# csi_tx_if_v2_0_TX_SHIM_VBUSP_MMR_CSI2TXIF_V2 register map
Vendor: Texas Instruments
Peripheral module from a debugger description file (folder J721S2).
Registers are 32-bit, read-write, reset 0x0 unless marked. A register's access mark holds for its fields unless they carry their own. Offsets are as the file gives them; lines under a group give offsets from that group; [hi:lo] are bit positions; {n}, {i} and the like mark numbered series; 'fields as' and 'values as' point back to an identical list; <NAME> marks a mode.

## csi_tx_if_v2_0_TX_SHIM_VBUSP_MMR_CSI2TXIF_V2
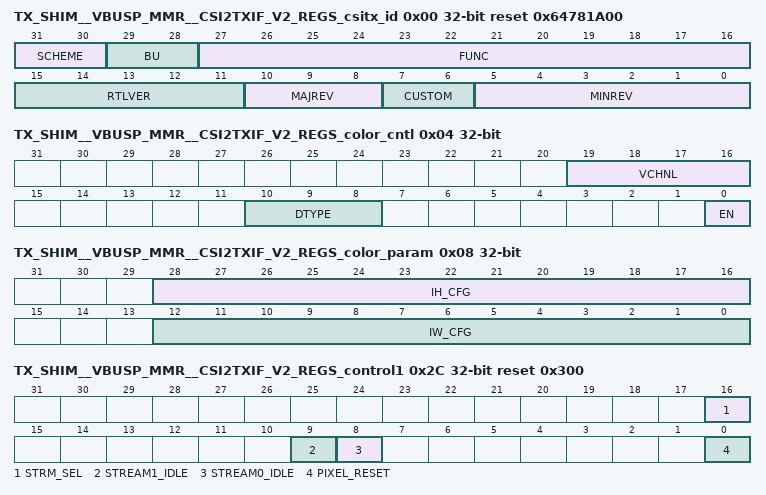
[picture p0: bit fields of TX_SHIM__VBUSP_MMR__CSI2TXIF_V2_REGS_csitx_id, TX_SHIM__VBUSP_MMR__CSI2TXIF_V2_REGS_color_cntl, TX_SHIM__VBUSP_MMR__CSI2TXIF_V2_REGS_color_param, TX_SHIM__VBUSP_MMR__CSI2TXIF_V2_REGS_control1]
0x00 TX_SHIM__VBUSP_MMR__CSI2TXIF_V2_REGS_csitx_id ro reset 0x64781A00 — PID
  [31:30] SCHEME
  [29:28] BU
  [27:16] FUNC — function
  [15:11] RTLVER — rtl version
  [10:8] MAJREV — major revision
  [7:6] CUSTOM — custom revision
  [5:0] MINREV — min revision
0x04 TX_SHIM__VBUSP_MMR__CSI2TXIF_V2_REGS_color_cntl — color bar control register
  [19:16] VCHNL — color bar virtual channel
  [10:8] DTYPE — color bar data type, data sel
  [0] EN — 1: enable
0x08 TX_SHIM__VBUSP_MMR__CSI2TXIF_V2_REGS_color_param — color bar frame parameters
  [28:16] IH_CFG — input height in units of pixels minus 1.
  [12:0] IW_CFG — input width in units of pixels minus 1.
0x0C TX_SHIM__VBUSP_MMR__CSI2TXIF_V2_REGS_color_start_delay — delay from starting first line after enabling
  [31:0] LINE_DELAY — delay in terms of main clock cycles before sending first line after enabling.
0x20 TX_SHIM__VBUSP_MMR__CSI2TXIF_V2_REGS_color_line_delay — last line start to next line start delay
  [31:0] LINE_DELAY — delay in terms of main clock cycles from line start to next line start
0x24 TX_SHIM__VBUSP_MMR__CSI2TXIF_V2_REGS_color_frame_delay — line start to next frame start delay
  [31:0] FRAME_DELAY — delay in terms of main clock cycles from last line start to start of next frame
0x2C TX_SHIM__VBUSP_MMR__CSI2TXIF_V2_REGS_control1 access per field reset 0x300 — control register for csi tx wrapper
  [16] STRM_SEL rw — select to switch dma versus retransmit interface mux, 0=dma, 1=retransmit
  [9] STREAM1_IDLE ro — indicates if stream interface is idle(1) or not(0)
  [8] STREAM0_IDLE ro — indicates if stream interface is idle(1) or not(0)
  [0] PIXEL_RESET rw — reset for the pixeal interface. 0=reset, 1 not in reset. this should be asserted till after you program the csi controller configuration registers
0x40 TX_SHIM__VBUSP_MMR__CSI2TXIF_V2_REGS_f2f_delay — last line start to next frame start. Configuration for each of 16 virtual channels.
  [31:0] DELAY — counter value delay of last line start of frame to first line of next frame
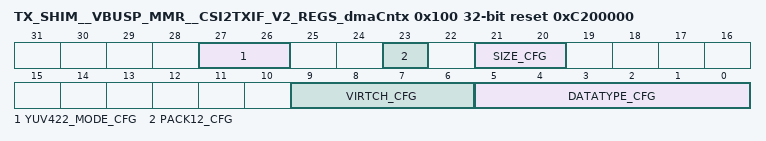
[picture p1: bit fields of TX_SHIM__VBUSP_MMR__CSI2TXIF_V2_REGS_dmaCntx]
0x100 TX_SHIM__VBUSP_MMR__CSI2TXIF_V2_REGS_dmaCntx reset 0xC200000 — DMA Channel Context. Configuration for each of 32 possible threads. Illegal to program 2 threads with same virtual channel and data type values
  [27:26] YUV422_MODE_CFG — yuv422 mode 00:UYVY, 01:VYUY, 10:YUYV, 11:YVYU
  [23] PACK12_CFG — pack12 format enable 0. used in conjunction with size for proper packing: not pack12 /n 1: pack12
  [21:20] SIZE_CFG — data size shift when unpacking, 00=8, 01=16, 10=32, 11=RSVD
  [9:6] VIRTCH_CFG — CSI virtual channel index. Supplied by MIPI CSI protocol to DPHY. For CSIver1.3 program 2MSb==0
  [5:0] DATATYPE_CFG — CSI data type. Supplied by MIPI CSI protocol to DPHY
0x104 TX_SHIM__VBUSP_MMR__CSI2TXIF_V2_REGS_l2l_delay — line to line delay. Configuration for each of 32 possible channel contexts.
  [31:0] DELAY — counter value delay line start to next line start within a frame
0x108 TX_SHIM__VBUSP_MMR__CSI2TXIF_V2_REGS_bytecnt — number of bytes in a line per context thread
  [15:0] BYTECNT — byte count in a line
0x10C TX_SHIM__VBUSP_MMR__CSI2TXIF_V2_REGS_l2f_delay — line to frame delay. Configuration for each of 32 possible channel contexts.
  [31:0] DELAY — counter value delay line end to end of frame
